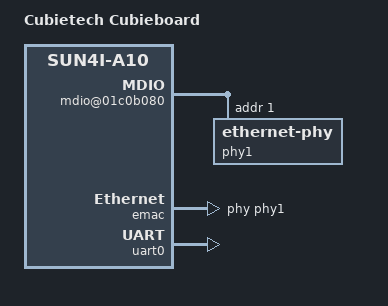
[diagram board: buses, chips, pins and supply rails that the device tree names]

/include/ "../sun4i-a10.dtsi"

/ {
        model = "Cubietech Cubieboard";
        compatible = "cubietech,a10-cubieboard", "allwinner,sun4i-a10";

        aliases {
                serial0 = &uart0;
                serial1 = &uart1;
        };

        chosen {
                bootargs = "earlyprintk console=ttyS0,115200";
        };

	soc@01c00000 {
		mdio@01c0b080 {
			status = "okay";

			phy1: ethernet-phy@1 {
				reg = <1>;
			};
		};

		emac: ethernet@01c0b000 {
			pinctrl-names = "default";
			pinctrl-0 = <&emac_pins_a>;
			phy = <&phy1>;
			status = "okay";
		};

		pinctrl@01c20800 {
			led_pins_cubieboard: led_pins@0 {
				allwinner,pins = "PH20", "PH21";
				allwinner,function = "gpio_out";
				allwinner,drive = <1>;
				allwinner,pull = <0>;
			};
		};

		uart0: serial@01c28000 {
			pinctrl-names = "default";
			pinctrl-0 = <&uart0_pins_a>;
			status = "okay";
		};
	};
};
